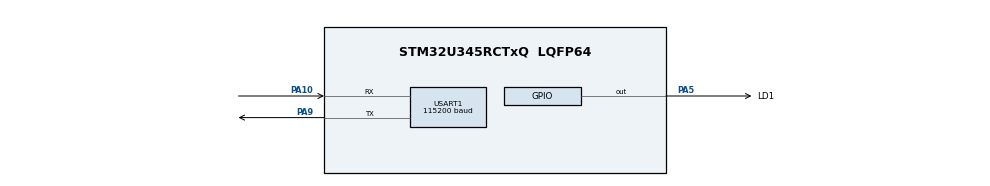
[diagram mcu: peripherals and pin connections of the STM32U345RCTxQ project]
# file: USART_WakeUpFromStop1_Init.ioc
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CORTEX_M33_NS.userName=CORTEX_M33
Mcu.Family=STM32U3
Mcu.Name=STM32U345RCTxQ
Mcu.Package=LQFP64
NVIC.PriorityGroup=NVIC_PRIORITYGROUP_4
NVIC.USART1_IRQn=true\:0\:0\:false\:false\:true\:true\:true\:true
PA10.GPIO_PuPd=GPIO_PULLUP
PA10.GPIO_Speed=GPIO_SPEED_FREQ_HIGH
PA10.Mode=Asynchronous
PA10.Signal=USART1_RX
PA5.GPIO_Label=LD1
PA5.GPIO_PuPd=GPIO_NOPULL
PA5.Signal=GPIO_Output
PA9.GPIO_PuPd=GPIO_PULLUP
PA9.GPIO_Speed=GPIO_SPEED_FREQ_HIGH
PA9.Mode=Asynchronous
PA9.Signal=USART1_TX
ProjectManager.HeapSize=0x200
ProjectManager.StackSize=0x400
ProjectManager.TargetToolchain=EWARM V9.20
RCC.ADCFreq_Value=3000000
RCC.AHBFreq_Value=3000000
RCC.APB1Freq_Value=3000000
RCC.APB1TimFreq_Value=3000000
RCC.APB2Freq_Value=3000000
RCC.APB2TimFreq_Value=3000000
RCC.APB3Freq_Value=3000000
RCC.CortexFreq_Value=375000
RCC.HCLKFreq_Value=3000000
RCC.HSE_VALUE=16000000
RCC.HSI48_VALUE=48000000
RCC.HSI_VALUE=16000000
RCC.LSE_VALUE=32768
RCC.LSIDIV_VALUE=32000
RCC.MSISDIV=RCC_MSI_DIV8
RCC.MSISSource=RCC_MSI_RC1
RCC.PWR_Regulator_Voltage_Scale=PWR_REGULATOR_VOLTAGE_SCALE1
RCC.SYSCLKFreq_VALUE=3000000
RCC.SYSCLKSource=RCC_SYSCLKSOURCE_MSIS
RCC.USART1CLockSelection=RCC_USART1CLKSOURCE_HSI
RCC.USBFreq_Value=3000000
USART1.AutoBaudRateEnableParam=UART_ADVFEATURE_AUTOBAUDRATE_DISABLE
USART1.BaudRate=115200
USART1.ClockPrescaler=PRESCALER_DIV1
USART1.DMADisableonRxErrorParam=ADVFEATURE_DMA_ENABLEONRXERROR
USART1.DataInvertParam=ADVFEATURE_DATAINV_DISABLE
USART1.FIFOMode=FIFOMODE_DISABLE
USART1.MSBFirstParam=ADVFEATURE_MSBFIRST_DISABLE
USART1.Mode=MODE_TX_RX
USART1.OneBitSampling=UART_ONE_BIT_SAMPLE_DISABLE
USART1.OverSampling=UART_OVERSAMPLING_16
USART1.OverrunDisableParam=ADVFEATURE_OVERRUN_ENABLE
USART1.Parity=PARITY_NONE
USART1.RXFIFOThreshold=RXFIFO_THRESHOLD_1EIGHTHFULL
USART1.RxPinLevelInvertParam=ADVFEATURE_RXINV_DISABLE
USART1.StopBits=STOPBITS_1
USART1.SwapParam=ADVFEATURE_SWAP_DISABLE
USART1.TXFIFOThreshold=TXFIFO_THRESHOLD_1EIGHTHFULL
USART1.TxPinLevelInvertParam=ADVFEATURE_TXINV_DISABLE
USART1.VirtualMode-Asynchronous=VM_ASYNC
USART1.WordLength=WORDLENGTH_8B
VP_ICACHE_VS_ICACHE.Mode=DirectMappedCache
VP_PWR_VS_DBSignals.Mode=DisableDeadBatterySignals
VP_PWR_VS_SECSignals.Mode=Security/Privilege
board=custom

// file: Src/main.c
/* USER CODE BEGIN Header */
/**
  ******************************************************************************
  * @file    Examples_LL/USART/USART_WakeUpFromStop1_Init/Src/main.c
  * @author  MCD Application Team
  * @brief   This example describes how to configure USART1 peripheral in Asynchronous mode
  *          for being able to wake from Stop 1 mode when a character is received on RX line using
  *          the STM32U3xx USART LL API.
  *          Peripheral initialization done using LL unitary services functions.
  ******************************************************************************
  * @attention"
  *
  * Copyright (c) 2026 STMicroelectronics.
  * All rights reserved.
  *
  * This software is licensed under terms that can be found in the LICENSE file
  * in the root directory of this software component.
  * If no LICENSE file comes with this software, it is provided AS-IS.
  *
  ******************************************************************************
  */
/* USER CODE END Header */
#include "main.h"

/* USER CODE BEGIN PV */

/**
  * @brief Variables used for character reception from PC Com port
  */
__IO uint8_t      ubFinalCharReceived = 0;
__IO uint32_t     ubReceivedChar;

/**
  * @brief Text string printed on PC Com port to inform MCU will enter in Stop 1 Mode
  */
uint8_t aTextInfo[] = "\r\nUSART1 Example : MCU will now enter in Stop 1 mode.\n\rEnter any character for waking up MCU.\r\n";

/* USER CODE END PV */

void SystemClock_Config(void);
static void MX_GPIO_Init(void);
static void MX_USART1_UART_Init(void);
static void MX_ICACHE_Init(void);
/* USER CODE BEGIN PFP */

void     LED_On(void);
void     LED_Off(void);
void     LED_Blinking(uint32_t Period);
void     LED_Blinking_3s(void);
void     Configure_PWR(void);
void     PrepareUSARTToStopMode(void);
void     EnterSTOP1Mode(void);
void     PrintInfo(void);
static void RestoreReferenceRunClock(void);

/* USER CODE END PFP */

/* USER CODE BEGIN 0 */

static void RestoreReferenceRunClock(void)
{
  LL_PWR_SetRegulatorSupply(LL_PWR_SMPS_SUPPLY);
  while (LL_PWR_IsActiveFlag_REGULATOR() == 0U)
  {
  }

  LL_PWR_SetRegulVoltageScaling(LL_PWR_REGU_VOLTAGE_SCALE1);
  while (LL_PWR_GetRegulCurrentVOS() != LL_PWR_REGU_VOLTAGE_SCALE1)
  {
  }

  LL_FLASH_SetLatency(LL_FLASH_LATENCY_0);
  while (LL_FLASH_GetLatency() != LL_FLASH_LATENCY_0)
  {
  }

  LL_RCC_MSIS_SetClockSource(LL_RCC_MSIS_CLOCK_SOURCE_RC1);
  LL_RCC_MSIS_SetClockDivision(LL_RCC_MSIS_CLOCK_SOURCE_RC_DIV_8);
  LL_RCC_MSI_SetMSIxClockRange();
  LL_RCC_SetSysClkSource(LL_RCC_SYS_CLKSOURCE_MSIS);
  while (LL_RCC_GetSysClkSource() != LL_RCC_SYS_CLKSOURCE_MSIS)
  {
  }

  LL_RCC_SetAHBPrescaler(LL_RCC_HCLK_SYSCLK_DIV_1);
  LL_RCC_SetAPB1Prescaler(LL_RCC_APB1_HCLK_DIV_1);
  LL_RCC_SetAPB2Prescaler(LL_RCC_APB2_HCLK_DIV_1);
  LL_RCC_SetAPB3Prescaler(LL_RCC_APB3_HCLK_DIV_1);

  LL_Init1msTick(3000000U);
  LL_SetSystemCoreClock(3000000U);
}

/* USER CODE END 0 */

int main(void)
{

  /* MCU Configuration--------------------------------------------------------*/

  /* Reset of all peripherals, Initializes the Flash interface and the Systick. */

  /* System interrupt init*/
  NVIC_SetPriorityGrouping(NVIC_PRIORITYGROUP_4);

  /* USER CODE BEGIN Init */

  Configure_PWR();

  /* USER CODE END Init */

  /* Configure the system clock */
  SystemClock_Config();

  /* USER CODE BEGIN SysInit */

  RestoreReferenceRunClock();

  /* USER CODE END SysInit */

  /* Initialize all configured peripherals */
  MX_GPIO_Init();
  MX_USART1_UART_Init();
  MX_ICACHE_Init();
  /* USER CODE BEGIN 2 */

  LL_RCC_SetStopWakeupClock(LL_RCC_STOP_WAKEUP_CLK_MSIS);

  /* Start main program loop :
     - make LED blink during 3 sec
     - Enter Stop 1 mode (LED turned Off)
     - Wait for any character received on USART1 RX line for waking up MCU
  */
  while (ubFinalCharReceived == 0)
  {
    /* LED blinks during 3 seconds */
    LED_Blinking_3s();

    /* Send Text Information on USART1 TX to PC Com port */
    PrintInfo();

    /* Prepare USART1 for entering Stop Mode */
    PrepareUSARTToStopMode();

    /* Enter Stop 1 mode */
    EnterSTOP1Mode();

    /* At this point, MCU just wakes up from Stop 1 mode */
  }

  /* USER CODE END 2 */

  /* Infinite loop */
  while (1)
  {

  }
}

void SystemClock_Config(void)
{

  /** Configure the main internal regulator output voltage
  */
  LL_PWR_SetRegulVoltageScaling(LL_PWR_REGU_VOLTAGE_SCALE1);
  while(LL_PWR_GetRegulCurrentVOS() != LL_PWR_REGU_VOLTAGE_SCALE1)
  {
  }

  /** Set Flash latency before switching to MSIS
  */
  LL_FLASH_SetLatency(LL_FLASH_LATENCY_2);
  while(LL_FLASH_GetLatency()!= LL_FLASH_LATENCY_2)
  {
  }

  LL_RCC_HSI_Enable();

   /* Wait till HSI is ready */
  while(LL_RCC_HSI_IsReady() != 1)
  {
  }

  LL_RCC_HSI_SetCalibTrimming(16);
  /** Activate MSIS as source
*/
  LL_RCC_MSIS_SetClockSource(LL_RCC_MSIS_CLOCK_SOURCE_RC1);
  LL_RCC_MSIS_SetClockDivision(LL_RCC_MSIS_CLOCK_SOURCE_RC_DIV_8);
  LL_RCC_MSI_SetMSIxClockRange();
  LL_RCC_SetSysClkSource(LL_RCC_SYS_CLKSOURCE_MSIS);

   /** Wait till System clock is ready
*/
  while(LL_RCC_GetSysClkSource() != LL_RCC_SYS_CLKSOURCE_MSIS)
  {
  }

  LL_RCC_SetAHBPrescaler(LL_RCC_HCLK_SYSCLK_DIV_1);
  LL_RCC_SetAPB1Prescaler(LL_RCC_APB1_HCLK_DIV_1);
  LL_RCC_SetAPB2Prescaler(LL_RCC_APB2_HCLK_DIV_1);
  LL_RCC_SetAPB3Prescaler(LL_RCC_APB3_HCLK_DIV_1);

  LL_Init1msTick(3000000);

  LL_SetSystemCoreClock(3000000);
}

static void MX_ICACHE_Init(void)
{

  /** Enable instruction cache in 1-way (direct mapped cache)
  */
  LL_ICACHE_SetMode(LL_ICACHE_1WAY);
  LL_ICACHE_Enable();

}

static void MX_USART1_UART_Init(void)
{

  LL_USART_InitTypeDef USART_InitStruct = {0};

  LL_GPIO_InitTypeDef GPIO_InitStruct = {0};

  LL_RCC_SetUSARTClockSource(LL_RCC_USART1_CLKSOURCE_HSI16);

  /* Peripheral clock enable */
  LL_APB2_GRP1_EnableClock(LL_APB2_GRP1_PERIPH_USART1);

  LL_AHB2_GRP1_EnableClock(LL_AHB2_GRP1_PERIPH_GPIOA);
  /**USART1 GPIO Configuration
  PA9   ------> USART1_TX
  PA10   ------> USART1_RX
  */
  GPIO_InitStruct.Pin = LL_GPIO_PIN_9|LL_GPIO_PIN_10;
  GPIO_InitStruct.Mode = LL_GPIO_MODE_ALTERNATE;
  GPIO_InitStruct.Speed = LL_GPIO_SPEED_FREQ_HIGH;
  GPIO_InitStruct.OutputType = LL_GPIO_OUTPUT_PUSHPULL;
  GPIO_InitStruct.Pull = LL_GPIO_PULL_UP;
  GPIO_InitStruct.Alternate = LL_GPIO_AF_7;
  LL_GPIO_Init(GPIOA, &GPIO_InitStruct);

  /* USART1 interrupt Init */
  NVIC_SetPriority(USART1_IRQn, NVIC_EncodePriority(NVIC_GetPriorityGrouping(),0, 0));
  NVIC_EnableIRQ(USART1_IRQn);

  /* USER CODE BEGIN USART1_Init 1 */
  LL_RCC_HSI_Enable();
  while (LL_RCC_HSI_IsReady() != 1U)
  {
  }

  LL_RCC_HSI_EnableInStopMode();
  LL_RCC_SetUSARTClockSource(LL_RCC_USART1_CLKSOURCE_HSI16);

  /* USER CODE END USART1_Init 1 */
  USART_InitStruct.PrescalerValue = LL_USART_PRESCALER_DIV1;
  USART_InitStruct.BaudRate = 115200;
  USART_InitStruct.DataWidth = LL_USART_DATAWIDTH_8B;
  USART_InitStruct.StopBits = LL_USART_STOPBITS_1;
  USART_InitStruct.Parity = LL_USART_PARITY_NONE;
  USART_InitStruct.TransferDirection = LL_USART_DIRECTION_TX_RX;
  USART_InitStruct.HardwareFlowControl = LL_USART_HWCONTROL_NONE;
  USART_InitStruct.OverSampling = LL_USART_OVERSAMPLING_16;
  LL_USART_Init(USART1, &USART_InitStruct);
  LL_USART_SetTXFIFOThreshold(USART1, LL_USART_FIFOTHRESHOLD_1_8);
  LL_USART_SetRXFIFOThreshold(USART1, LL_USART_FIFOTHRESHOLD_1_8);
  LL_USART_DisableFIFO(USART1);
  LL_USART_ConfigAsyncMode(USART1);
  LL_USART_Enable(USART1);
  /* USER CODE BEGIN USART1_Init 2 */
  while ((!(LL_USART_IsActiveFlag_TEACK(USART1))) || (!(LL_USART_IsActiveFlag_REACK(USART1))))
  {
  }
  /* USER CODE END USART1_Init 2 */

}

static void MX_GPIO_Init(void)
{
  LL_GPIO_InitTypeDef GPIO_InitStruct = {0};

  /* GPIO Ports Clock Enable */
  LL_AHB2_GRP1_EnableClock(LL_AHB2_GRP1_PERIPH_GPIOA);

  /**/
  LL_GPIO_ResetOutputPin(LD1_GPIO_Port, LD1_Pin);

  /**/
  GPIO_InitStruct.Pin = LD1_Pin;
  GPIO_InitStruct.Mode = LL_GPIO_MODE_OUTPUT;
  GPIO_InitStruct.Speed = LL_GPIO_SPEED_FREQ_LOW;
  GPIO_InitStruct.OutputType = LL_GPIO_OUTPUT_PUSHPULL;
  GPIO_InitStruct.Pull = LL_GPIO_PULL_NO;
  LL_GPIO_Init(LD1_GPIO_Port, &GPIO_InitStruct);

}

/* USER CODE BEGIN 4 */

/**
  * @brief  Function to configure and initialize PWR IP.
  * @param  None
  * @retval None
  */
void Configure_PWR(void)
{
  /* Enable Power Clock */
  LL_AHB1_GRP2_EnableClock(LL_AHB1_GRP2_PERIPH_PWR);

  /* Ensure that MSIS is wake-up system clock */
  LL_RCC_SetStopWakeupClock(LL_RCC_STOP_WAKEUP_CLK_MSIS);
}

/**
  * @brief  Function to configure USART1 for being ready to enter Stop 1 mode.
  * @param  None
  * @retval None
  */
void PrepareUSARTToStopMode(void)
{

  /* Empty RX Fifo before entering Stop 1 mode (Otherwise, characters already present in FIFO
     will lead to immediate wake up */
  while (LL_USART_IsActiveFlag_RXNE(USART1))
  {
    /* Read Received character. RXNE flag is cleared by reading of RDR register */
    ubReceivedChar = LL_USART_ReceiveData8(USART1);
  }

  /* Clear OVERRUN flag */
  LL_USART_ClearFlag_ORE(USART1);
  LL_USART_ClearFlag_FE(USART1);
  LL_USART_ClearFlag_NE(USART1);

  /* Make sure that no USART1 transfer is on-going */
  while (LL_USART_IsActiveFlag_BUSY(USART1) == 1)
  {
  }
  /* Make sure that USART1 is ready to receive */
  while (LL_USART_IsActiveFlag_REACK(USART1) == 0)
  {
  }

  LL_USART_Disable(USART1);
  LL_USART_Enable(USART1);
  while (LL_USART_IsActiveFlag_REACK(USART1) == 0)
  {
  }

  /* About to enter stop mode: switch off LED */
  LED_Off();

  /* Configure USART1 transfer interrupts : */
  /* Clear WUF flag and enable the UART Wake Up from stop mode Interrupt */
  LL_USART_EnableIT_ERROR(USART1);
  LL_USART_EnableIT_RXNE(USART1);

  /* Enable Wake Up From Stop */
  LL_USART_EnableInStopMode(USART1);
}

/**
  * @brief  Function to enter in Stop 1 mode.
  * @param  None
  * @retval None
  */
void EnterSTOP1Mode(void)
{
  uint32_t systick_ctrl;

  systick_ctrl = SysTick->CTRL;
  SysTick->CTRL &= ~SysTick_CTRL_TICKINT_Msk;

  CLEAR_BIT(DBGMCU->CR, DBGMCU_CR_DBG_STOP);
  LL_PWR_SetPowerMode(LL_PWR_MODE_STOP1);
  LL_LPM_EnableDeepSleep();
  __WFI();

  LL_LPM_EnableSleep();
  SysTick->CTRL = systick_ctrl;
}

/**
  * @brief  Send Txt information message on USART1 Tx line (to PC Com port).
  * @param  None
  * @retval None
  */
void PrintInfo(void)
{
  uint32_t index = 0;

  /* Send characters one per one, until last char to be sent */
  for (index = 0; index < sizeof(aTextInfo); index++)
  {
    /* Wait for TXE flag to be raised */
    while (!LL_USART_IsActiveFlag_TXE(USART1))
    {
    }

    /* Write character in Transmit Data register.
       TXE flag is cleared by writing data in TDR register */
    LL_USART_TransmitData8(USART1, aTextInfo[index]);
  }

  /* Wait for TC flag to be raised for last char */
  while (!LL_USART_IsActiveFlag_TC(USART1))
  {
  }
}

/**
  * @brief  Turn-on LD1.
  * @param  None
  * @retval None
  */
void LED_On(void)
{
  /* Turn LD1 on */
  LL_GPIO_SetOutputPin(LD1_GPIO_Port, LD1_Pin);
}

/**
  * @brief  Turn-off LD1.
  * @param  None
  * @retval None
  */
void LED_Off(void)
{
  /* Turn LD1 off */
  LL_GPIO_ResetOutputPin(LD1_GPIO_Port, LD1_Pin);
}

/**
  * @brief  Set LD1 to Blinking mode for an infinite loop (toggle period based on value provided as input parameter).
  * @param  Period : Period of time (in ms) between each toggling of LED
  *   This parameter can be user defined values. Pre-defined values used in that example are :
  *     @arg LED_BLINK_FAST : Fast Blinking
  *     @arg LED_BLINK_SLOW : Slow Blinking
  *     @arg LED_BLINK_ERROR : Error specific Blinking
  * @retval None
  */
void LED_Blinking(uint32_t Period)
{
  /* Toggle IO in an infinite loop */
  while (1)
  {
    LL_GPIO_TogglePin(LD1_GPIO_Port, LD1_Pin);
    LL_mDelay(Period);
  }
}

/**
  * @brief  Set LD1 to Blinking mode during 3s.
  * @param  None
  * @retval None
  */
void LED_Blinking_3s(void)
{
  uint32_t index = 0;

  /* Toggle IO in during 3s (15*200ms) */
  for (index = 0; index < 15; index++)
  {
    LL_GPIO_TogglePin(LD1_GPIO_Port, LD1_Pin);
    LL_mDelay(200);
  }
}

/******************************************************************************/
/*   IRQ HANDLER TREATMENT Functions                                          */
/******************************************************************************/

/**
  * @brief  Function called from USART1 IRQ Handler when RXNE flag is set
  *         Function is in charge of reading character received on USART1 RX line.
  * @param  None
  * @retval None
  */
void USART1_CharReception_Callback(void)
{
  /* Read Received character. RXNE flag is cleared by reading of RDR register */
  ubReceivedChar = LL_USART_ReceiveData8(USART1);

  /* Check if received value is corresponding to specific one : S or s */
  if ((ubReceivedChar == 'S') || (ubReceivedChar == 's'))
  {
    /* Turn LD1 On : Expected character has been received */
    LED_On();

    /* End of program : set boolean for main loop exit */
    ubFinalCharReceived = 1;
  }

  /* Echo received character on TX */
  LL_USART_TransmitData8(USART1, ubReceivedChar);
}

/**
  * @brief  Function called in case of error detected in USART IT Handler
  * @param  None
  * @retval None
  */
void Error_Callback(void)
{
  /* Disable USART1_IRQn */
  NVIC_DisableIRQ(USART1_IRQn);

  /* Unexpected event : Set LD1 to Blinking mode to indicate error occurs */
  LED_Blinking(LED_BLINK_ERROR);
}

/* USER CODE END 4 */

void Error_Handler(void)
{
}
#ifdef USE_FULL_ASSERT
/**
  * @brief  Reports the name of the source file and the source line number
  *         where the assert_param error has occurred.
  * @param  file: pointer to the source file name
  * @param  line: assert_param error line source number
  * @retval None
  */
void assert_failed(uint8_t *file, uint32_t line)
{
  /* USER CODE BEGIN 6 */
  /* User can add his own implementation to report the file name and line number,
     tex: printf("Wrong parameters value: file %s on line %d\r\n", file, line) */
  /*Infinite Loop */
  while(1)
  {
  }
  /* USER CODE END 6 */
}
#endif /* USE_FULL_ASSERT */
